# STM32F302VCY7 register map
File version: 1.0
Registers are 32-bit, access not given, reset 0x0 unless marked. A register's access mark holds for its fields unless they carry their own. Offsets are from the block's base; [hi:lo] are bit positions; {n}, {i} and the like mark numbered series; 'fields as' and 'values as' point back to an identical list.

## PWR
Base 0x40007000
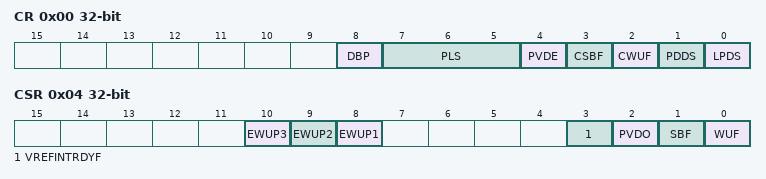
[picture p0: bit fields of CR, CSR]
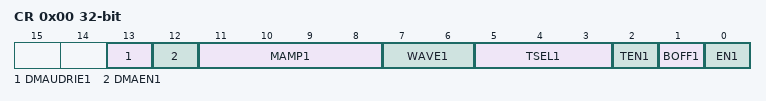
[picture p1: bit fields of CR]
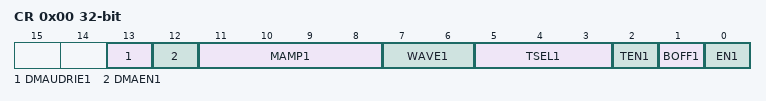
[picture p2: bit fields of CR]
0x00 CR
  [8] DBP, [7:5] PLS, [4] PVDE, [3] CSBF, [2] CWUF, [1] PDDS, [0] LPDS
0x04 CSR
  [10] EWUP3, [9] EWUP2, [8] EWUP1, [3] VREFINTRDYF, [2] PVDO, [1] SBF, [0] WUF

## DAC
Base 0x40007400
0x00 CR
  [13] DMAUDRIE1, [12] DMAEN1, [11:8] MAMP1, [7:6] WAVE1, [5:3] TSEL1, [2] TEN1, [1] BOFF1, [0] EN1
0x04 SWTRIGR
  [0] SWTRIG1
0x08 DHR12R1
  [11:0] DACC1DHR
0x0C DHR12L1
  [15:4] DACC1DHR
0x10 DHR8R1
  [7:0] DACC1DHR
0x20 DHR12RD
  [11:0] DACC1DHR
0x24 DHR12LD
  [15:4] DACC1DHR
0x28 DHR8RD
  [7:0] DACC1DHR
0x2C DOR1
  [11:0] DACC1DOR
0x34 SR
  [13] DMAUDR1

## DAC1
Base 0x40007400
0x00 CR
  [13] DMAUDRIE1, [12] DMAEN1, [11:8] MAMP1, [7:6] WAVE1, [5:3] TSEL1, [2] TEN1, [1] BOFF1, [0] EN1
0x04 SWTRIGR
  [0] SWTRIG1
0x08 DHR12R1
  [11:0] DACC1DHR
0x0C DHR12L1
  [15:4] DACC1DHR
0x10 DHR8R1
  [7:0] DACC1DHR
0x20 DHR12RD
  [11:0] DACC1DHR
0x24 DHR12LD
  [15:4] DACC1DHR
0x28 DHR8RD
  [7:0] DACC1DHR
0x2C DOR1
  [11:0] DACC1DOR
0x34 SR
  [13] DMAUDR1

## SYSCFG
Base 0x40010000
0x00 CFGR1
  [31:26] FPU_IE, [23] ENCODER_MODE_TIM3, [23:22] ENCODER_MODE_TIM4, [21] I2C2_FMP, [20] I2C1_FMP, [n+10] I2C_PB{n}_FMP (n=6..9), [13] TIM6DAC1Ch1_DMA_RMP, [12] TIM17_DMA_RMP, [11] TIM16_DMA_RMP, [13:8] DMA_RMP, [7] DAC1_TRIG1_RMP, [6] TIM1_ITR3_RMP, [5] USB_IT_RMP, [1:0] MEM_MODE
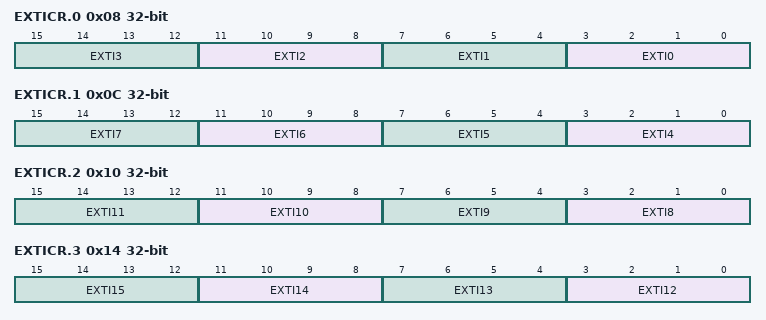
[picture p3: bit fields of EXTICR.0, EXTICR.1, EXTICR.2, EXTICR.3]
0x08 EXTICR.0
  [4n+3:4n] EXTI{n} (n=0..3)
0x0C EXTICR.1
  [4n-13:4n-16] EXTI{n} (n=4..7)
0x10 EXTICR.2
  [4n-29:4n-32] EXTI{n} (n=8..11)
0x14 EXTICR.3
  [4n-45:4n-48] EXTI{n} (n=12..15)
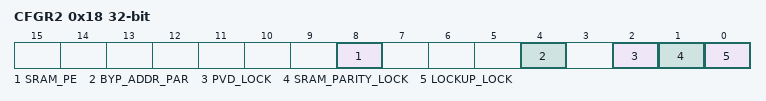
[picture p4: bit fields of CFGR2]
0x18 CFGR2
  [8] SRAM_PE, [4] BYP_ADDR_PAR, [2] PVD_LOCK, [1] SRAM_PARITY_LOCK, [0] LOCKUP_LOCK

## COMP1
Base 0x4001001C
Same registers: COMP2 0x40010020, COMP12_COMMON 0x40010020, COMP4 0x40010028, COMP6 0x40010030
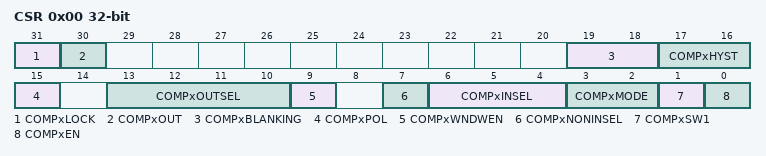
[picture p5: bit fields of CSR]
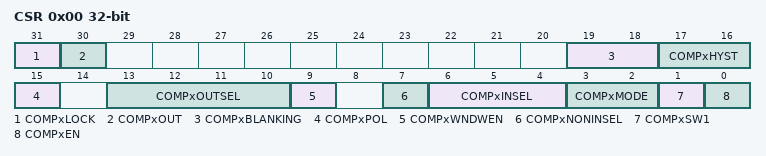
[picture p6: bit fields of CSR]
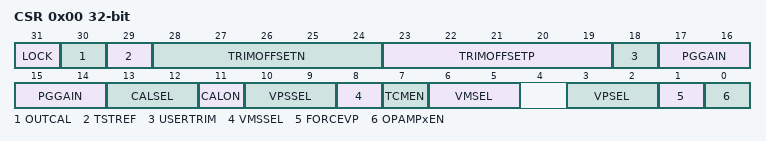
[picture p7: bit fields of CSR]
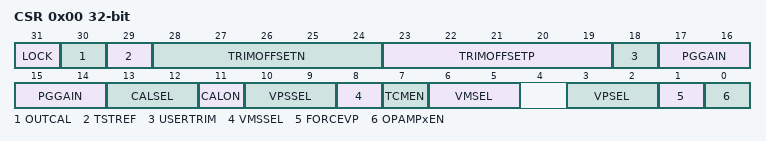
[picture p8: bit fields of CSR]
0x00 CSR
  [31] COMPxLOCK, [30] COMPxOUT, [19:18] COMPxBLANKING, [17:16] COMPxHYST, [15] COMPxPOL, [13:10] COMPxOUTSEL, [9] COMPxWNDWEN, [7] COMPxNONINSEL, [6:4] COMPxINSEL, [3:2] COMPxMODE, [1] COMPxSW1, [0] COMPxEN

## COMP
Base 0x4001001C
0x00 CSR
  [31] COMPxLOCK, [30] COMPxOUT, [19:18] COMPxBLANKING, [17:16] COMPxHYST, [15] COMPxPOL, [13:10] COMPxOUTSEL, [9] COMPxWNDWEN, [7] COMPxNONINSEL, [6:4] COMPxINSEL, [3:2] COMPxMODE, [1] COMPxSW1, [0] COMPxEN

## OPAMP1
Base 0x40010038
Same registers: OPAMP2 0x4001003C
0x00 CSR
  [31] LOCK, [30] OUTCAL, [29] TSTREF, [28:24] TRIMOFFSETN, [23:19] TRIMOFFSETP, [18] USERTRIM, [17:14] PGGAIN, [13:12] CALSEL, [11] CALON, [10:9] VPSSEL, [8] VMSSEL, [7] TCMEN, [6:5] VMSEL, [3:2] VPSEL, [1] FORCEVP, [0] OPAMPxEN

## OPAMP
Base 0x40010038
0x00 CSR
  [31] LOCK, [30] OUTCAL, [29] TSTREF, [28:24] TRIMOFFSETN, [23:19] TRIMOFFSETP, [18] USERTRIM, [17:14] PGGAIN, [13:12] CALSEL, [11] CALON, [10:9] VPSSEL, [8] VMSSEL, [7] TCMEN, [6:5] VMSEL, [3:2] VPSEL, [1] FORCEVP, [0] OPAMPxEN

## EXTI
Base 0x40010400
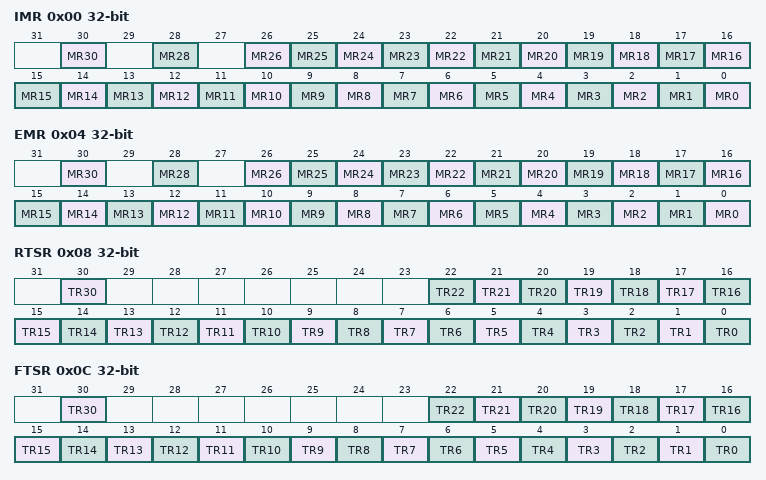
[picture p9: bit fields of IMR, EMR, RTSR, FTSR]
0x00 IMR
  [30] MR30, [28] MR28, [n] MR{n} (n=0..26)
0x04 EMR
  [30] MR30, [28] MR28, [n] MR{n} (n=0..26)
0x08 RTSR
  [30] TR30, [n] TR{n} (n=0..22)
0x0C FTSR
  [30] TR30, [n] TR{n} (n=0..22)
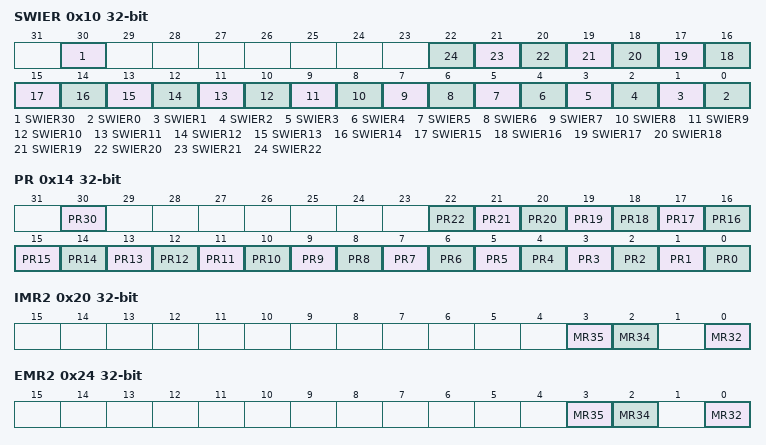
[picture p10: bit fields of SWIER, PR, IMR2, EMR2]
0x10 SWIER
  [30] SWIER30, [n] SWIER{n} (n=0..22)
0x14 PR
  [30] PR30, [n] PR{n} (n=0..22)
0x20 IMR2
  [3] MR35, [2] MR34, [0] MR32
0x24 EMR2
  [3] MR35, [2] MR34, [0] MR32
0x28 RTSR2
  [0] TR32
0x2C FTSR2
  [0] TR32
0x30 SWIER2
  [0] SWIER32
0x34 PR2
  [0] PR32

## DMA1
Base 0x40020000
Same registers: DMA2 0x40020400
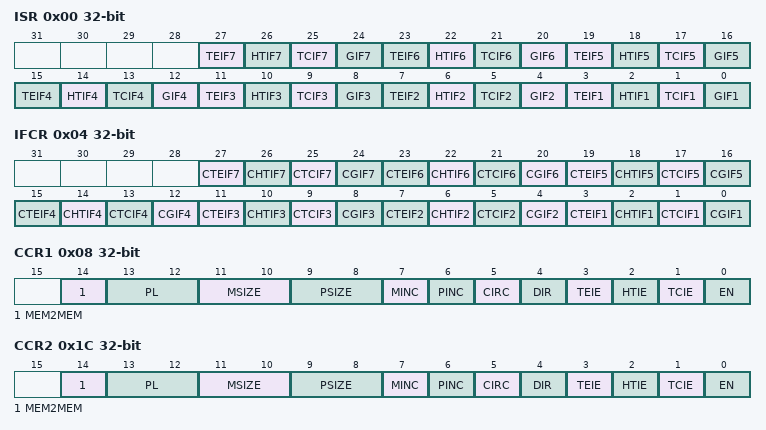
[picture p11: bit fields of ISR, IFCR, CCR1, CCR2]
0x00 ISR
  [4n-1] TEIF{n} (n=1..7), [4n-2] HTIF{n} (n=1..7), [4n-3] TCIF{n} (n=1..7), [4n-4] GIF{n} (n=1..7)
0x04 IFCR
  [4n-1] CTEIF{n} (n=1..7), [4n-2] CHTIF{n} (n=1..7), [4n-3] CTCIF{n} (n=1..7), [4n-4] CGIF{n} (n=1..7)
0x08 CCR1
  [14] MEM2MEM, [13:12] PL, [11:10] MSIZE, [9:8] PSIZE, [7] MINC, [6] PINC, [5] CIRC, [4] DIR, [3] TEIE, [2] HTIE, [1] TCIE, [0] EN
0x0C CNDTR1
  [15:0] NDT
0x10 CPAR1
  [31:0] PA
{0x0+0x14*i} CMAR{i} (i=1..7)
  [31:0] MA
0x1C CCR2
  fields as CCR1
0x20 CNDTR2
  [15:0] NDT
0x24 CPAR2
  [31:0] PA
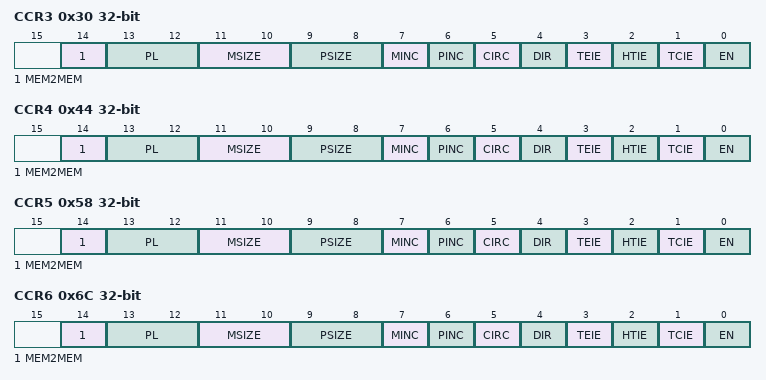
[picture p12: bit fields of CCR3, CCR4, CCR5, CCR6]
0x30 CCR3
  fields as CCR1
0x34 CNDTR3
  [15:0] NDT
0x38 CPAR3
  [31:0] PA
0x44 CCR4
  fields as CCR1
0x48 CNDTR4
  [15:0] NDT
0x4C CPAR4
  [31:0] PA
0x58 CCR5
  fields as CCR1
0x5C CNDTR5
  [15:0] NDT
0x60 CPAR5
  [31:0] PA
0x6C CCR6
  fields as CCR1
0x70 CNDTR6
  [15:0] NDT
0x74 CPAR6
  [31:0] PA
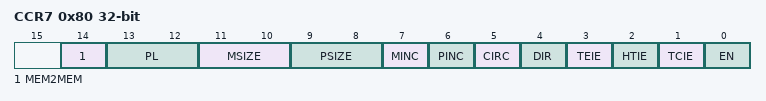
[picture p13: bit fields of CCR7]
0x80 CCR7
  fields as CCR1
0x84 CNDTR7
  [15:0] NDT
0x88 CPAR7
  [31:0] PA
